# WKUP_CTRL_MMR0_CFG0 register map
Vendor: Texas Instruments
Registers are 32-bit, read-write, reset 0x0 unless marked. A register's access mark holds for its fields unless they carry their own. Offsets are as the file gives them; [hi:lo] are bit positions.

## WKUP_CTRL_MMR0_CFG0 (part 5 of 11)
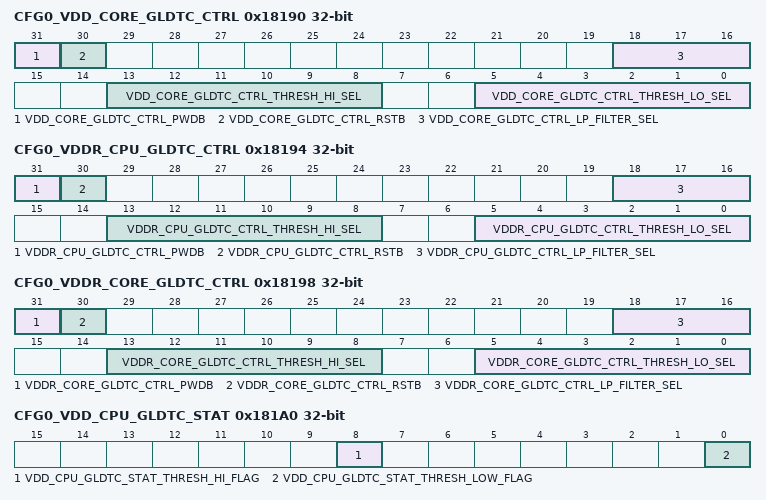
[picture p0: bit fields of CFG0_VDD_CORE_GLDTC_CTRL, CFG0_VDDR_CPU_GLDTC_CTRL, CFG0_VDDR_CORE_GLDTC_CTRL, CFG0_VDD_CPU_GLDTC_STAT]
0x18190 CFG0_VDD_CORE_GLDTC_CTRL — Controls the voltage glitch detector circuit monitoring the VDD_CORE voltage domain
  [31] VDD_CORE_GLDTC_CTRL_PWDB — Power down - active low. 0 - Disable all functions 1 - Enable glitch detectors
  [30] VDD_CORE_GLDTC_CTRL_RSTB — Reset - active low. To ensure proper operation, rstb must be not be de-asserted for at least 100 ns after power-up (pwdb de-asserted). Additionally, rstb must be toggled low at least 200 ns after any change in threshold or low-pass filter settings to prevent abnormal trigger events. 0 - Reset glitch detector flags 1 - Glitch detection flags are enabled
  [18:16] VDD_CORE_GLDTC_CTRL_LP_FILTER_SEL — Selects the glitch detect low-pass filter bandwidth Field values (Others are reserved): 3'b000 - 150 kHz 3'b001 - 125 kHz 3'b010 - 100 kHz 3'b011 - 80 kHz 3'b100 - 60 kHz 3'b101 - 45 kHz 3'b110 - 30 kHz 3'b111 - 15 kHz
  [13:8] VDD_CORE_GLDTC_CTRL_THRESH_HI_SEL — Selects the high voltage glitch threshold as a percentage of the monitored voltage Field values (Others are reserved): 6'b000000 - 93.5% of VDD 6'b000001 - 94.0% of VDD 6'b000010 - 94.5% of VDD 6'b000011 - 95.0% of VDD 6'b000100 - 95.5% of VDD 6'b000101 - 96.0% of VDD 6'b000110 - 96.5% of VDD 6'b000111 - 97.0% of VDD 6'b001000 - 97.5% of VDD 6'b001001 - 98.0% of VDD 6'b001010 - 98.5% of VDD 6'b001011 - 99.0% of VDD 6'b001100 - 99.5% of VDD 6'b001101 - 100.0% of VDD 6'b001110 - 100.5% of VDD 6'b001111 - 101.0% of VDD 6'b010000 - 101.5% of VDD 6'b010001 - 102.0% of VDD 6'b010010 - 102.5% of VDD 6'b010011 - 103.0% of VDD 6'b010100 - 103.5% of VDD 6'b010101 - 104.0% of VDD 6'b010110 - 104.5% of VDD 6'b010111 - 105.0% of VDD 6'b011000 - 105.5% of VDD 6'b011001 - 106.0% of VDD 6'b011010 - 106.5% of VDD 6'b011011 - 107.0% of VDD 6'b011100 - 107.5% of VDD 6'b011101 - 108.0% of VDD 6'b011110 - 108.5% of VDD 6'b011111 - 109.0% of VDD 6'b100000 - 109.5% of VDD 6'b100001 - 110.0% of VDD 6'b100010 - 111.0% of VDD 6'b100011 - 112.0% of VDD 6'b100100 - 113.0% of VDD 6'b100101 - 114.0% of VDD 6'b100110 - 115.0% of VDD 6'b100111 - 116.0% of VDD 6'b101000 - 117.0% of VDD 6'b101001 - 118.0% of VDD 6'b101010 - 119.0% of VDD 6'b101011 - 120.0% of VDD 6'b101100 - 121.0% of VDD 6'b101101 - 122.0% of VDD 6'b101110 - 123.0% of VDD 6'b101111 - 124.0% of VDD 6'b110000 - 125.0% of VDD 6'b110001 - 126.0% of VDD 6'b110010 - 127.0% of VDD 6'b110011 - 128.0% of VDD 6'b110100 - 129.0% of VDD 6'b110101 - 130.0% of VDD 6'b110110 - 131.0% of VDD 6'b110111 - 132.0% of VDD 6'b111000 - 133.0% of VDD 6'b111001 - 134.0% of VDD 6'b111010 - 135.0% of VDD 6'b111011 - 136.0% of VDD 6'b111100 - 137.0% of VDD 6'b111101 - 138.0% of VDD 6'b111110 - 139.0% of VDD 6'b111111 - 140.0% of VDD
  [5:0] VDD_CORE_GLDTC_CTRL_THRESH_LO_SEL — Selects the low voltage glitch threshold as a percentage of the monitored voltage Field values (Others are reserved): 6'b000000 - 106.5% of VDD 6'b000001 - 106.0% of VDD 6'b000010 - 105.5% of VDD 6'b000011 - 105.0% of VDD 6'b000100 - 104.5% of VDD 6'b000101 - 104.0% of VDD 6'b000110 - 103.5% of VDD 6'b000111 - 103.0% of VDD 6'b001000 - 102.5% of VDD 6'b001001 - 102.0% of VDD 6'b001010 - 101.5% of VDD 6'b001011 - 101.0% of VDD 6'b001100 - 100.5% of VDD 6'b001101 - 100.0% of VDD 6'b001110 - 99.5% of VDD 6'b001111 - 99.0% of VDD 6'b010000 - 98.5% of VDD 6'b010001 - 98.0% of VDD 6'b010010 - 97.5% of VDD 6'b010011 - 97.0% of VDD 6'b010100 - 96.5% of VDD 6'b010101 - 96.0% of VDD 6'b010110 - 95.5% of VDD 6'b010111 - 95.0% of VDD 6'b011000 - 94.5% of VDD 6'b011001 - 94.0% of VDD 6'b011010 - 93.5% of VDD 6'b011011 - 93.0% of VDD 6'b011100 - 92.5% of VDD 6'b011101 - 92.0% of VDD 6'b011110 - 91.5% of VDD 6'b011111 - 91.0% of VDD 6'b100000 - 90.5% of VDD 6'b100001 - 90.0% of VDD 6'b100010 - 89.0% of VDD 6'b100011 - 88.0% of VDD 6'b100100 - 87.0% of VDD 6'b100101 - 86.0% of VDD 6'b100110 - 85.0% of VDD 6'b100111 - 84.0% of VDD 6'b101000 - 83.0% of VDD 6'b101001 - 82.0% of VDD 6'b101010 - 81.0% of VDD 6'b101011 - 80.0% of VDD 6'b101100 - 79.0% of VDD 6'b101101 - 78.0% of VDD 6'b101110 - 77.0% of VDD 6'b101111 - 76.0% of VDD 6'b110000 - 75.0% of VDD 6'b110001 - 74.0% of VDD 6'b110010 - 73.0% of VDD 6'b110011 - 72.0% of VDD 6'b110100 - 71.0% of VDD 6'b110101 - 70.0% of VDD 6'b110110 - 69.0% of VDD 6'b110111 - 68.0% of VDD 6'b111000 - 67.0% of VDD 6'b111001 - 66.0% of VDD 6'b111010 - 65.0% of VDD 6'b111011 - 64.0% of VDD 6'b111100 - 63.0% of VDD 6'b111101 - 62.0% of VDD 6'b111110 - 61.0% of VDD 6'b111111 - 60.0% of VDD
0x18194 CFG0_VDDR_CPU_GLDTC_CTRL — Controls the voltage glitch detector circuit monitoring the VDDR_CPU 0 voltage domain
  [31] VDDR_CPU_GLDTC_CTRL_PWDB — Power down - active low. 0 - Disable all functions 1 - Enable glitch detectors
  [30] VDDR_CPU_GLDTC_CTRL_RSTB — Reset - active low. To ensure proper operation, rstb must be not be de-asserted for at least 100 ns after power-up (pwdb de-asserted). Additionally, rstb must be toggled low at least 200 ns after any change in threshold or low-pass filter settings to prevent abnormal trigger events. 0 - Reset glitch detector flags 1 - Glitch detection flags are enabled
  [18:16] VDDR_CPU_GLDTC_CTRL_LP_FILTER_SEL — Selects the glitch detect low-pass filter bandwidth Field values (Others are reserved): 3'b000 - 150 kHz 3'b001 - 125 kHz 3'b010 - 100 kHz 3'b011 - 80 kHz 3'b100 - 60 kHz 3'b101 - 45 kHz 3'b110 - 30 kHz 3'b111 - 15 kHz
  [13:8] VDDR_CPU_GLDTC_CTRL_THRESH_HI_SEL — Selects the high voltage glitch threshold as a percentage of the monitored voltage Field values (Others are reserved): 6'b000000 - 93.5% of VDD 6'b000001 - 94.0% of VDD 6'b000010 - 94.5% of VDD 6'b000011 - 95.0% of VDD 6'b000100 - 95.5% of VDD 6'b000101 - 96.0% of VDD 6'b000110 - 96.5% of VDD 6'b000111 - 97.0% of VDD 6'b001000 - 97.5% of VDD 6'b001001 - 98.0% of VDD 6'b001010 - 98.5% of VDD 6'b001011 - 99.0% of VDD 6'b001100 - 99.5% of VDD 6'b001101 - 100.0% of VDD 6'b001110 - 100.5% of VDD 6'b001111 - 101.0% of VDD 6'b010000 - 101.5% of VDD 6'b010001 - 102.0% of VDD 6'b010010 - 102.5% of VDD 6'b010011 - 103.0% of VDD 6'b010100 - 103.5% of VDD 6'b010101 - 104.0% of VDD 6'b010110 - 104.5% of VDD 6'b010111 - 105.0% of VDD 6'b011000 - 105.5% of VDD 6'b011001 - 106.0% of VDD 6'b011010 - 106.5% of VDD 6'b011011 - 107.0% of VDD 6'b011100 - 107.5% of VDD 6'b011101 - 108.0% of VDD 6'b011110 - 108.5% of VDD 6'b011111 - 109.0% of VDD 6'b100000 - 109.5% of VDD 6'b100001 - 110.0% of VDD 6'b100010 - 111.0% of VDD 6'b100011 - 112.0% of VDD 6'b100100 - 113.0% of VDD 6'b100101 - 114.0% of VDD 6'b100110 - 115.0% of VDD 6'b100111 - 116.0% of VDD 6'b101000 - 117.0% of VDD 6'b101001 - 118.0% of VDD 6'b101010 - 119.0% of VDD 6'b101011 - 120.0% of VDD 6'b101100 - 121.0% of VDD 6'b101101 - 122.0% of VDD 6'b101110 - 123.0% of VDD 6'b101111 - 124.0% of VDD 6'b110000 - 125.0% of VDD 6'b110001 - 126.0% of VDD 6'b110010 - 127.0% of VDD 6'b110011 - 128.0% of VDD 6'b110100 - 129.0% of VDD 6'b110101 - 130.0% of VDD 6'b110110 - 131.0% of VDD 6'b110111 - 132.0% of VDD 6'b111000 - 133.0% of VDD 6'b111001 - 134.0% of VDD 6'b111010 - 135.0% of VDD 6'b111011 - 136.0% of VDD 6'b111100 - 137.0% of VDD 6'b111101 - 138.0% of VDD 6'b111110 - 139.0% of VDD 6'b111111 - 140.0% of VDD
  [5:0] VDDR_CPU_GLDTC_CTRL_THRESH_LO_SEL — Selects the low voltage glitch threshold as a percentage of the monitored voltage Field values (Others are reserved): 6'b000000 - 106.5% of VDD 6'b000001 - 106.0% of VDD 6'b000010 - 105.5% of VDD 6'b000011 - 105.0% of VDD 6'b000100 - 104.5% of VDD 6'b000101 - 104.0% of VDD 6'b000110 - 103.5% of VDD 6'b000111 - 103.0% of VDD 6'b001000 - 102.5% of VDD 6'b001001 - 102.0% of VDD 6'b001010 - 101.5% of VDD 6'b001011 - 101.0% of VDD 6'b001100 - 100.5% of VDD 6'b001101 - 100.0% of VDD 6'b001110 - 99.5% of VDD 6'b001111 - 99.0% of VDD 6'b010000 - 98.5% of VDD 6'b010001 - 98.0% of VDD 6'b010010 - 97.5% of VDD 6'b010011 - 97.0% of VDD 6'b010100 - 96.5% of VDD 6'b010101 - 96.0% of VDD 6'b010110 - 95.5% of VDD 6'b010111 - 95.0% of VDD 6'b011000 - 94.5% of VDD 6'b011001 - 94.0% of VDD 6'b011010 - 93.5% of VDD 6'b011011 - 93.0% of VDD 6'b011100 - 92.5% of VDD 6'b011101 - 92.0% of VDD 6'b011110 - 91.5% of VDD 6'b011111 - 91.0% of VDD 6'b100000 - 90.5% of VDD 6'b100001 - 90.0% of VDD 6'b100010 - 89.0% of VDD 6'b100011 - 88.0% of VDD 6'b100100 - 87.0% of VDD 6'b100101 - 86.0% of VDD 6'b100110 - 85.0% of VDD 6'b100111 - 84.0% of VDD 6'b101000 - 83.0% of VDD 6'b101001 - 82.0% of VDD 6'b101010 - 81.0% of VDD 6'b101011 - 80.0% of VDD 6'b101100 - 79.0% of VDD 6'b101101 - 78.0% of VDD 6'b101110 - 77.0% of VDD 6'b101111 - 76.0% of VDD 6'b110000 - 75.0% of VDD 6'b110001 - 74.0% of VDD 6'b110010 - 73.0% of VDD 6'b110011 - 72.0% of VDD 6'b110100 - 71.0% of VDD 6'b110101 - 70.0% of VDD 6'b110110 - 69.0% of VDD 6'b110111 - 68.0% of VDD 6'b111000 - 67.0% of VDD 6'b111001 - 66.0% of VDD 6'b111010 - 65.0% of VDD 6'b111011 - 64.0% of VDD 6'b111100 - 63.0% of VDD 6'b111101 - 62.0% of VDD 6'b111110 - 61.0% of VDD 6'b111111 - 60.0% of VDD
0x18198 CFG0_VDDR_CORE_GLDTC_CTRL — Controls the voltage glitch detector circuit monitoring the VDDR_CORE voltage domain
  [31] VDDR_CORE_GLDTC_CTRL_PWDB — Power down - active low. 0 - Disable all functions 1 - Enable glitch detectors
  [30] VDDR_CORE_GLDTC_CTRL_RSTB — Reset - active low. To ensure proper operation, rstb must be not be de-asserted for at least 100 ns after power-up (pwdb de-asserted). Additionally, rstb must be toggled low at least 200 ns after any change in threshold or low-pass filter settings to prevent abnormal trigger events. 0 - Reset glitch detector flags 1 - Glitch detection flags are enabled
  [18:16] VDDR_CORE_GLDTC_CTRL_LP_FILTER_SEL — Selects the glitch detect low-pass filter bandwidth Field values (Others are reserved): 3'b000 - 150 kHz 3'b001 - 125 kHz 3'b010 - 100 kHz 3'b011 - 80 kHz 3'b100 - 60 kHz 3'b101 - 45 kHz 3'b110 - 30 kHz 3'b111 - 15 kHz
  [13:8] VDDR_CORE_GLDTC_CTRL_THRESH_HI_SEL — Selects the high voltage glitch threshold as a percentage of the monitored voltage Field values (Others are reserved): 6'b000000 - 93.5% of VDD 6'b000001 - 94.0% of VDD 6'b000010 - 94.5% of VDD 6'b000011 - 95.0% of VDD 6'b000100 - 95.5% of VDD 6'b000101 - 96.0% of VDD 6'b000110 - 96.5% of VDD 6'b000111 - 97.0% of VDD 6'b001000 - 97.5% of VDD 6'b001001 - 98.0% of VDD 6'b001010 - 98.5% of VDD 6'b001011 - 99.0% of VDD 6'b001100 - 99.5% of VDD 6'b001101 - 100.0% of VDD 6'b001110 - 100.5% of VDD 6'b001111 - 101.0% of VDD 6'b010000 - 101.5% of VDD 6'b010001 - 102.0% of VDD 6'b010010 - 102.5% of VDD 6'b010011 - 103.0% of VDD 6'b010100 - 103.5% of VDD 6'b010101 - 104.0% of VDD 6'b010110 - 104.5% of VDD 6'b010111 - 105.0% of VDD 6'b011000 - 105.5% of VDD 6'b011001 - 106.0% of VDD 6'b011010 - 106.5% of VDD 6'b011011 - 107.0% of VDD 6'b011100 - 107.5% of VDD 6'b011101 - 108.0% of VDD 6'b011110 - 108.5% of VDD 6'b011111 - 109.0% of VDD 6'b100000 - 109.5% of VDD 6'b100001 - 110.0% of VDD 6'b100010 - 111.0% of VDD 6'b100011 - 112.0% of VDD 6'b100100 - 113.0% of VDD 6'b100101 - 114.0% of VDD 6'b100110 - 115.0% of VDD 6'b100111 - 116.0% of VDD 6'b101000 - 117.0% of VDD 6'b101001 - 118.0% of VDD 6'b101010 - 119.0% of VDD 6'b101011 - 120.0% of VDD 6'b101100 - 121.0% of VDD 6'b101101 - 122.0% of VDD 6'b101110 - 123.0% of VDD 6'b101111 - 124.0% of VDD 6'b110000 - 125.0% of VDD 6'b110001 - 126.0% of VDD 6'b110010 - 127.0% of VDD 6'b110011 - 128.0% of VDD 6'b110100 - 129.0% of VDD 6'b110101 - 130.0% of VDD 6'b110110 - 131.0% of VDD 6'b110111 - 132.0% of VDD 6'b111000 - 133.0% of VDD 6'b111001 - 134.0% of VDD 6'b111010 - 135.0% of VDD 6'b111011 - 136.0% of VDD 6'b111100 - 137.0% of VDD 6'b111101 - 138.0% of VDD 6'b111110 - 139.0% of VDD 6'b111111 - 140.0% of VDD
  [5:0] VDDR_CORE_GLDTC_CTRL_THRESH_LO_SEL — Selects the low voltage glitch threshold as a percentage of the monitored voltage Field values (Others are reserved): 6'b000000 - 106.5% of VDD 6'b000001 - 106.0% of VDD 6'b000010 - 105.5% of VDD 6'b000011 - 105.0% of VDD 6'b000100 - 104.5% of VDD 6'b000101 - 104.0% of VDD 6'b000110 - 103.5% of VDD 6'b000111 - 103.0% of VDD 6'b001000 - 102.5% of VDD 6'b001001 - 102.0% of VDD 6'b001010 - 101.5% of VDD 6'b001011 - 101.0% of VDD 6'b001100 - 100.5% of VDD 6'b001101 - 100.0% of VDD 6'b001110 - 99.5% of VDD 6'b001111 - 99.0% of VDD 6'b010000 - 98.5% of VDD 6'b010001 - 98.0% of VDD 6'b010010 - 97.5% of VDD 6'b010011 - 97.0% of VDD 6'b010100 - 96.5% of VDD 6'b010101 - 96.0% of VDD 6'b010110 - 95.5% of VDD 6'b010111 - 95.0% of VDD 6'b011000 - 94.5% of VDD 6'b011001 - 94.0% of VDD 6'b011010 - 93.5% of VDD 6'b011011 - 93.0% of VDD 6'b011100 - 92.5% of VDD 6'b011101 - 92.0% of VDD 6'b011110 - 91.5% of VDD 6'b011111 - 91.0% of VDD 6'b100000 - 90.5% of VDD 6'b100001 - 90.0% of VDD 6'b100010 - 89.0% of VDD 6'b100011 - 88.0% of VDD 6'b100100 - 87.0% of VDD 6'b100101 - 86.0% of VDD 6'b100110 - 85.0% of VDD 6'b100111 - 84.0% of VDD 6'b101000 - 83.0% of VDD 6'b101001 - 82.0% of VDD 6'b101010 - 81.0% of VDD 6'b101011 - 80.0% of VDD 6'b101100 - 79.0% of VDD 6'b101101 - 78.0% of VDD 6'b101110 - 77.0% of VDD 6'b101111 - 76.0% of VDD 6'b110000 - 75.0% of VDD 6'b110001 - 74.0% of VDD 6'b110010 - 73.0% of VDD 6'b110011 - 72.0% of VDD 6'b110100 - 71.0% of VDD 6'b110101 - 70.0% of VDD 6'b110110 - 69.0% of VDD 6'b110111 - 68.0% of VDD 6'b111000 - 67.0% of VDD 6'b111001 - 66.0% of VDD 6'b111010 - 65.0% of VDD 6'b111011 - 64.0% of VDD 6'b111100 - 63.0% of VDD 6'b111101 - 62.0% of VDD 6'b111110 - 61.0% of VDD 6'b111111 - 60.0% of VDD
0x181A0 CFG0_VDD_CPU_GLDTC_STAT ro — Shows the status of the voltage glitch detector circuit monitoring the VDD_CPU voltage domain
  [8] VDD_CPU_GLDTC_STAT_THRESH_HI_FLAG — High voltage flag. This flag is cleared by clearing the VDD_CPU_GLDTC_CTRL_rstb bit. 0 - No high voltage detected 1 - Voltage above the high voltage threshold was detected.
  [0] VDD_CPU_GLDTC_STAT_THRESH_LOW_FLAG — Low voltage flag. This flag is cleared by clearing the VDD_CPU_GLDTC_CTRL_rstb bit. 0 - No low voltage detected 1 - Voltage below the low voltage threshold was detected.
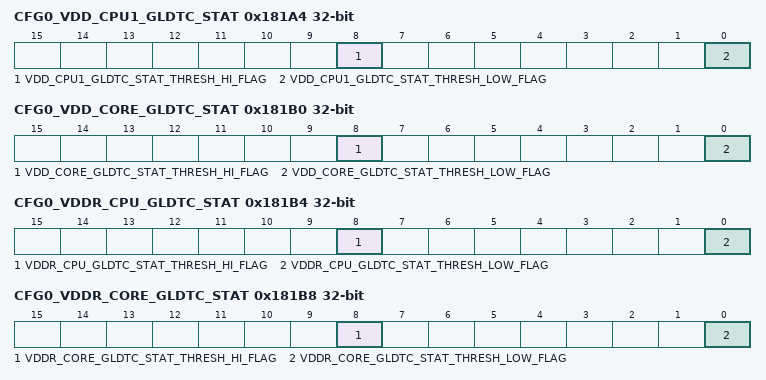
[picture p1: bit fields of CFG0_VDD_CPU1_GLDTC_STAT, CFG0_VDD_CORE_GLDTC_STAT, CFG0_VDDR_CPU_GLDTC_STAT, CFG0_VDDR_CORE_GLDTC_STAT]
0x181A4 CFG0_VDD_CPU1_GLDTC_STAT ro — Shows the status of the voltage glitch detector circuit monitoring the VDD_CPU1 voltage domain (Used for VDD_DDR0)
  [8] VDD_CPU1_GLDTC_STAT_THRESH_HI_FLAG — High voltage flag. This flag is cleared by clearing the VDD_CPU1_GLDTC_CTRL_rstb bit. 0 - No high voltage detected 1 - Voltage above the high voltage threshold was detected.
  [0] VDD_CPU1_GLDTC_STAT_THRESH_LOW_FLAG — Low voltage flag. This flag is cleared by clearing the VDD_CPU1_GLDTC_CTRL_rstb bit. 0 - No low voltage detected 1 - Voltage below the low voltage threshold was detected.
0x181B0 CFG0_VDD_CORE_GLDTC_STAT ro — Shows the status of the voltage glitch detector circuit monitoring the VDD_CORE voltage domain
  [8] VDD_CORE_GLDTC_STAT_THRESH_HI_FLAG — High voltage flag. This flag is cleared by clearing the VDD_CORE_GLDTC_CTRL_rstb bit. 0 - No high voltage detected 1 - Voltage above the high voltage threshold was detected.
  [0] VDD_CORE_GLDTC_STAT_THRESH_LOW_FLAG — Low voltage flag. This flag is cleared by clearing the VDD_CORE_GLDTC_CTRL_rstb bit. 0 - No low voltage detected 1 - Voltage below the low voltage threshold was detected.
0x181B4 CFG0_VDDR_CPU_GLDTC_STAT ro — Shows the status of the voltage glitch detector circuit monitoring the VDDR_CPU voltage domain
  [8] VDDR_CPU_GLDTC_STAT_THRESH_HI_FLAG — High voltage flag. This flag is cleared by clearing the VDDR_CPU_GLDTC_CTRL_rstb bit. 0 - No high voltage detected 1 - Voltage above the high voltage threshold was detected.
  [0] VDDR_CPU_GLDTC_STAT_THRESH_LOW_FLAG — Low voltage flag. This flag is cleared by clearing the VDDR_CPU_GLDTC_CTRL_rstb bit. 0 - No low voltage detected 1 - Voltage below the low voltage threshold was detected.
0x181B8 CFG0_VDDR_CORE_GLDTC_STAT ro — Shows the status of the voltage glitch detector circuit monitoring the VDDR_CORE voltage domain
  [8] VDDR_CORE_GLDTC_STAT_THRESH_HI_FLAG — High voltage flag. This flag is cleared by clearing the VDDR_CORE_GLDTC_CTRL_rstb bit. 0 - No high voltage detected 1 - Voltage above the high voltage threshold was detected.
  [0] VDDR_CORE_GLDTC_STAT_THRESH_LOW_FLAG — Low voltage flag. This flag is cleared by clearing the VDDR_CORE_GLDTC_CTRL_rstb bit. 0 - No low voltage detected 1 - Voltage below the low voltage threshold was detected.
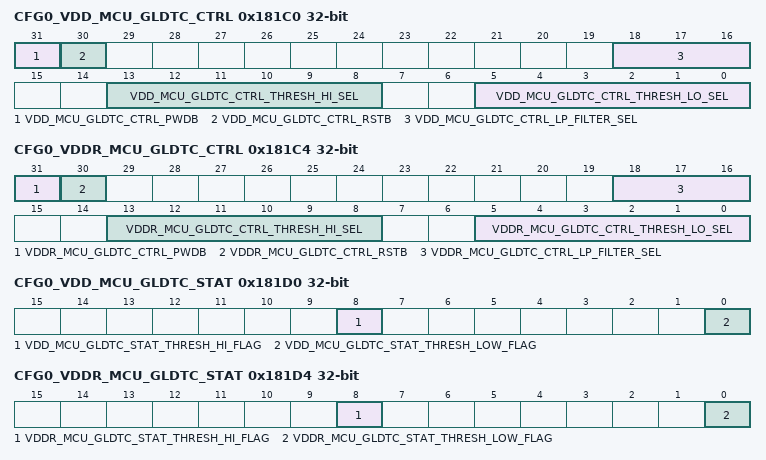
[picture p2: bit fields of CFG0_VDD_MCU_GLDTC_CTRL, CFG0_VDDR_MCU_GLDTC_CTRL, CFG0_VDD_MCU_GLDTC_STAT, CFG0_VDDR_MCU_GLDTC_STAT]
0x181C0 CFG0_VDD_MCU_GLDTC_CTRL — Controls the voltage glitch detector circuit monitoring the VDD_MCU voltage domain
  [31] VDD_MCU_GLDTC_CTRL_PWDB — Power down - active low. 0 - Disable all functions 1 - Enable glitch detectors
  [30] VDD_MCU_GLDTC_CTRL_RSTB — Reset - active low. To ensure proper operation, rstb must be not be de-asserted for at least 100 ns after power-up (pwdb de-asserted). Additionally, rstb must be toggled low at least 200 ns after any change in threshold or low-pass filter settings to prevent abnormal trigger events. 0 - Reset glitch detector flags 1 - Glitch detection flags are enabled
  [18:16] VDD_MCU_GLDTC_CTRL_LP_FILTER_SEL — Selects the glitch detect low-pass filter bandwidth Field values (Others are reserved): 3'b000 - 150 kHz 3'b001 - 125 kHz 3'b010 - 100 kHz 3'b011 - 80 kHz 3'b100 - 60 kHz 3'b101 - 45 kHz 3'b110 - 30 kHz 3'b111 - 15 kHz
  [13:8] VDD_MCU_GLDTC_CTRL_THRESH_HI_SEL — Selects the high voltage glitch threshold as a percentage of the monitored voltage Field values (Others are reserved): 6'b000000 - 93.5% of VDD 6'b000001 - 94.0% of VDD 6'b000010 - 94.5% of VDD 6'b000011 - 95.0% of VDD 6'b000100 - 95.5% of VDD 6'b000101 - 96.0% of VDD 6'b000110 - 96.5% of VDD 6'b000111 - 97.0% of VDD 6'b001000 - 97.5% of VDD 6'b001001 - 98.0% of VDD 6'b001010 - 98.5% of VDD 6'b001011 - 99.0% of VDD 6'b001100 - 99.5% of VDD 6'b001101 - 100.0% of VDD 6'b001110 - 100.5% of VDD 6'b001111 - 101.0% of VDD 6'b010000 - 101.5% of VDD 6'b010001 - 102.0% of VDD 6'b010010 - 102.5% of VDD 6'b010011 - 103.0% of VDD 6'b010100 - 103.5% of VDD 6'b010101 - 104.0% of VDD 6'b010110 - 104.5% of VDD 6'b010111 - 105.0% of VDD 6'b011000 - 105.5% of VDD 6'b011001 - 106.0% of VDD 6'b011010 - 106.5% of VDD 6'b011011 - 107.0% of VDD 6'b011100 - 107.5% of VDD 6'b011101 - 108.0% of VDD 6'b011110 - 108.5% of VDD 6'b011111 - 109.0% of VDD 6'b100000 - 109.5% of VDD 6'b100001 - 110.0% of VDD 6'b100010 - 111.0% of VDD 6'b100011 - 112.0% of VDD 6'b100100 - 113.0% of VDD 6'b100101 - 114.0% of VDD 6'b100110 - 115.0% of VDD 6'b100111 - 116.0% of VDD 6'b101000 - 117.0% of VDD 6'b101001 - 118.0% of VDD 6'b101010 - 119.0% of VDD 6'b101011 - 120.0% of VDD 6'b101100 - 121.0% of VDD 6'b101101 - 122.0% of VDD 6'b101110 - 123.0% of VDD 6'b101111 - 124.0% of VDD 6'b110000 - 125.0% of VDD 6'b110001 - 126.0% of VDD 6'b110010 - 127.0% of VDD 6'b110011 - 128.0% of VDD 6'b110100 - 129.0% of VDD 6'b110101 - 130.0% of VDD 6'b110110 - 131.0% of VDD 6'b110111 - 132.0% of VDD 6'b111000 - 133.0% of VDD 6'b111001 - 134.0% of VDD 6'b111010 - 135.0% of VDD 6'b111011 - 136.0% of VDD 6'b111100 - 137.0% of VDD 6'b111101 - 138.0% of VDD 6'b111110 - 139.0% of VDD 6'b111111 - 140.0% of VDD
  [5:0] VDD_MCU_GLDTC_CTRL_THRESH_LO_SEL — Selects the low voltage glitch threshold as a percentage of the monitored voltage Field values (Others are reserved): 6'b000000 - 106.5% of VDD 6'b000001 - 106.0% of VDD 6'b000010 - 105.5% of VDD 6'b000011 - 105.0% of VDD 6'b000100 - 104.5% of VDD 6'b000101 - 104.0% of VDD 6'b000110 - 103.5% of VDD 6'b000111 - 103.0% of VDD 6'b001000 - 102.5% of VDD 6'b001001 - 102.0% of VDD 6'b001010 - 101.5% of VDD 6'b001011 - 101.0% of VDD 6'b001100 - 100.5% of VDD 6'b001101 - 100.0% of VDD 6'b001110 - 99.5% of VDD 6'b001111 - 99.0% of VDD 6'b010000 - 98.5% of VDD 6'b010001 - 98.0% of VDD 6'b010010 - 97.5% of VDD 6'b010011 - 97.0% of VDD 6'b010100 - 96.5% of VDD 6'b010101 - 96.0% of VDD 6'b010110 - 95.5% of VDD 6'b010111 - 95.0% of VDD 6'b011000 - 94.5% of VDD 6'b011001 - 94.0% of VDD 6'b011010 - 93.5% of VDD 6'b011011 - 93.0% of VDD 6'b011100 - 92.5% of VDD 6'b011101 - 92.0% of VDD 6'b011110 - 91.5% of VDD 6'b011111 - 91.0% of VDD 6'b100000 - 90.5% of VDD 6'b100001 - 90.0% of VDD 6'b100010 - 89.0% of VDD 6'b100011 - 88.0% of VDD 6'b100100 - 87.0% of VDD 6'b100101 - 86.0% of VDD 6'b100110 - 85.0% of VDD 6'b100111 - 84.0% of VDD 6'b101000 - 83.0% of VDD 6'b101001 - 82.0% of VDD 6'b101010 - 81.0% of VDD 6'b101011 - 80.0% of VDD 6'b101100 - 79.0% of VDD 6'b101101 - 78.0% of VDD 6'b101110 - 77.0% of VDD 6'b101111 - 76.0% of VDD 6'b110000 - 75.0% of VDD 6'b110001 - 74.0% of VDD 6'b110010 - 73.0% of VDD 6'b110011 - 72.0% of VDD 6'b110100 - 71.0% of VDD 6'b110101 - 70.0% of VDD 6'b110110 - 69.0% of VDD 6'b110111 - 68.0% of VDD 6'b111000 - 67.0% of VDD 6'b111001 - 66.0% of VDD 6'b111010 - 65.0% of VDD 6'b111011 - 64.0% of VDD 6'b111100 - 63.0% of VDD 6'b111101 - 62.0% of VDD 6'b111110 - 61.0% of VDD 6'b111111 - 60.0% of VDD
0x181C4 CFG0_VDDR_MCU_GLDTC_CTRL — Controls the voltage glitch detector circuit monitoring the VDDR_MCU voltage domain
  [31] VDDR_MCU_GLDTC_CTRL_PWDB — Power down - active low. 0 - Disable all functions 1 - Enable glitch detectors
  [30] VDDR_MCU_GLDTC_CTRL_RSTB — Reset - active low. To ensure proper operation, rstb must be not be de-asserted for at least 100 ns after power-up (pwdb de-asserted). Additionally, rstb must be toggled low at least 200 ns after any change in threshold or low-pass filter settings to prevent abnormal trigger events. 0 - Reset glitch detector flags 1 - Glitch detection flags are enabled
  [18:16] VDDR_MCU_GLDTC_CTRL_LP_FILTER_SEL — Selects the glitch detect low-pass filter bandwidth Field values (Others are reserved): 3'b000 - 150 kHz 3'b001 - 125 kHz 3'b010 - 100 kHz 3'b011 - 80 kHz 3'b100 - 60 kHz 3'b101 - 45 kHz 3'b110 - 30 kHz 3'b111 - 15 kHz
  [13:8] VDDR_MCU_GLDTC_CTRL_THRESH_HI_SEL — Selects the high voltage glitch threshold as a percentage of the monitored voltage Field values (Others are reserved): 6'b000000 - 93.5% of VDD 6'b000001 - 94.0% of VDD 6'b000010 - 94.5% of VDD 6'b000011 - 95.0% of VDD 6'b000100 - 95.5% of VDD 6'b000101 - 96.0% of VDD 6'b000110 - 96.5% of VDD 6'b000111 - 97.0% of VDD 6'b001000 - 97.5% of VDD 6'b001001 - 98.0% of VDD 6'b001010 - 98.5% of VDD 6'b001011 - 99.0% of VDD 6'b001100 - 99.5% of VDD 6'b001101 - 100.0% of VDD 6'b001110 - 100.5% of VDD 6'b001111 - 101.0% of VDD 6'b010000 - 101.5% of VDD 6'b010001 - 102.0% of VDD 6'b010010 - 102.5% of VDD 6'b010011 - 103.0% of VDD 6'b010100 - 103.5% of VDD 6'b010101 - 104.0% of VDD 6'b010110 - 104.5% of VDD 6'b010111 - 105.0% of VDD 6'b011000 - 105.5% of VDD 6'b011001 - 106.0% of VDD 6'b011010 - 106.5% of VDD 6'b011011 - 107.0% of VDD 6'b011100 - 107.5% of VDD 6'b011101 - 108.0% of VDD 6'b011110 - 108.5% of VDD 6'b011111 - 109.0% of VDD 6'b100000 - 109.5% of VDD 6'b100001 - 110.0% of VDD 6'b100010 - 111.0% of VDD 6'b100011 - 112.0% of VDD 6'b100100 - 113.0% of VDD 6'b100101 - 114.0% of VDD 6'b100110 - 115.0% of VDD 6'b100111 - 116.0% of VDD 6'b101000 - 117.0% of VDD 6'b101001 - 118.0% of VDD 6'b101010 - 119.0% of VDD 6'b101011 - 120.0% of VDD 6'b101100 - 121.0% of VDD 6'b101101 - 122.0% of VDD 6'b101110 - 123.0% of VDD 6'b101111 - 124.0% of VDD 6'b110000 - 125.0% of VDD 6'b110001 - 126.0% of VDD 6'b110010 - 127.0% of VDD 6'b110011 - 128.0% of VDD 6'b110100 - 129.0% of VDD 6'b110101 - 130.0% of VDD 6'b110110 - 131.0% of VDD 6'b110111 - 132.0% of VDD 6'b111000 - 133.0% of VDD 6'b111001 - 134.0% of VDD 6'b111010 - 135.0% of VDD 6'b111011 - 136.0% of VDD 6'b111100 - 137.0% of VDD 6'b111101 - 138.0% of VDD 6'b111110 - 139.0% of VDD 6'b111111 - 140.0% of VDD
  [5:0] VDDR_MCU_GLDTC_CTRL_THRESH_LO_SEL — Selects the low voltage glitch threshold as a percentage of the monitored voltage Field values (Others are reserved): 6'b000000 - 106.5% of VDD 6'b000001 - 106.0% of VDD 6'b000010 - 105.5% of VDD 6'b000011 - 105.0% of VDD 6'b000100 - 104.5% of VDD 6'b000101 - 104.0% of VDD 6'b000110 - 103.5% of VDD 6'b000111 - 103.0% of VDD 6'b001000 - 102.5% of VDD 6'b001001 - 102.0% of VDD 6'b001010 - 101.5% of VDD 6'b001011 - 101.0% of VDD 6'b001100 - 100.5% of VDD 6'b001101 - 100.0% of VDD 6'b001110 - 99.5% of VDD 6'b001111 - 99.0% of VDD 6'b010000 - 98.5% of VDD 6'b010001 - 98.0% of VDD 6'b010010 - 97.5% of VDD 6'b010011 - 97.0% of VDD 6'b010100 - 96.5% of VDD 6'b010101 - 96.0% of VDD 6'b010110 - 95.5% of VDD 6'b010111 - 95.0% of VDD 6'b011000 - 94.5% of VDD 6'b011001 - 94.0% of VDD 6'b011010 - 93.5% of VDD 6'b011011 - 93.0% of VDD 6'b011100 - 92.5% of VDD 6'b011101 - 92.0% of VDD 6'b011110 - 91.5% of VDD 6'b011111 - 91.0% of VDD 6'b100000 - 90.5% of VDD 6'b100001 - 90.0% of VDD 6'b100010 - 89.0% of VDD 6'b100011 - 88.0% of VDD 6'b100100 - 87.0% of VDD 6'b100101 - 86.0% of VDD 6'b100110 - 85.0% of VDD 6'b100111 - 84.0% of VDD 6'b101000 - 83.0% of VDD 6'b101001 - 82.0% of VDD 6'b101010 - 81.0% of VDD 6'b101011 - 80.0% of VDD 6'b101100 - 79.0% of VDD 6'b101101 - 78.0% of VDD 6'b101110 - 77.0% of VDD 6'b101111 - 76.0% of VDD 6'b110000 - 75.0% of VDD 6'b110001 - 74.0% of VDD 6'b110010 - 73.0% of VDD 6'b110011 - 72.0% of VDD 6'b110100 - 71.0% of VDD 6'b110101 - 70.0% of VDD 6'b110110 - 69.0% of VDD 6'b110111 - 68.0% of VDD 6'b111000 - 67.0% of VDD 6'b111001 - 66.0% of VDD 6'b111010 - 65.0% of VDD 6'b111011 - 64.0% of VDD 6'b111100 - 63.0% of VDD 6'b111101 - 62.0% of VDD 6'b111110 - 61.0% of VDD 6'b111111 - 60.0% of VDD
0x181D0 CFG0_VDD_MCU_GLDTC_STAT ro — Shows the status of the voltage glitch detector circuit monitoring the VDD_MCU voltage domain
  [8] VDD_MCU_GLDTC_STAT_THRESH_HI_FLAG — High voltage flag. This flag is cleared by clearing the VDD_MCU_GLDTC_CTRL_rstb bit. 0 - No high voltage detected 1 - Voltage above the high voltage threshold was detected.
  [0] VDD_MCU_GLDTC_STAT_THRESH_LOW_FLAG — Low voltage flag. This flag is cleared by clearing the VDD_MCU_GLDTC_CTRL_rstb bit. 0 - No low voltage detected 1 - Voltage below the low voltage threshold was detected.
0x181D4 CFG0_VDDR_MCU_GLDTC_STAT ro — Shows the status of the voltage glitch detector circuit monitoring the VDDR_MCU voltage domain
  [8] VDDR_MCU_GLDTC_STAT_THRESH_HI_FLAG — High voltage flag. This flag is cleared by clearing the VDDR_MCU_GLDTC_CTRL_rstb bit. 0 - No high voltage detected 1 - Voltage above the high voltage threshold was detected.
  [0] VDDR_MCU_GLDTC_STAT_THRESH_LOW_FLAG — Low voltage flag. This flag is cleared by clearing the VDDR_MCU_GLDTC_CTRL_rstb bit. 0 - No low voltage detected 1 - Voltage below the low voltage threshold was detected.
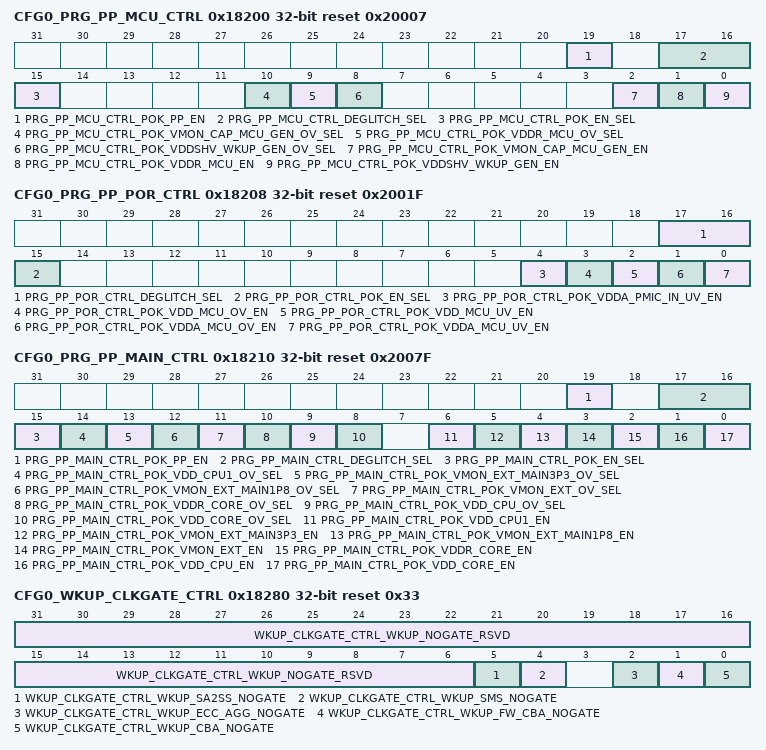
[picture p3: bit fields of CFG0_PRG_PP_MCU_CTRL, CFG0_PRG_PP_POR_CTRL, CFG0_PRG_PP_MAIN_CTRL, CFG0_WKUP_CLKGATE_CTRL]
0x18200 CFG0_PRG_PP_MCU_CTRL reset 0x20007 — Configures the MCU PRG_PP controller
  [19] PRG_PP_MCU_CTRL_POK_PP_EN — POK ping-pong enable. When set, enables automatic switching between undervoltage and overvoltage detection on VDDSHV_WKUP_GENERAL, VDDR_MCU and VMON_CAP_MCU_GENERAL POKs. This bit has no effect if the POK's ov_sel bit = 1. 0 - No pingpong operation. UV/OV operation selected by each POK ov_sel bit 1 - Pingpong operation enabled .
  [17:16] PRG_PP_MCU_CTRL_DEGLITCH_SEL — Deglitch period for PRG_PP_MCU POKs Field values (Others are reserved): 2'b00 - 5 us 2'b01 - 10 us 2'b10 - 15 us 2'b11 - 20 us
  [15] PRG_PP_MCU_CTRL_POK_EN_SEL — Select POK enable source 0 - POK enables come from hardware tie-offs (tie-offs are 0 on this device so all POKs are disabled on power-up) 1 - POK enables come from PRG_PP_MCU_CTRL register
  [10] PRG_PP_MCU_CTRL_POK_VMON_CAP_MCU_GEN_OV_SEL — Force VMON_CAP_MCU_GENERAL POK overvoltage detection. If this bit is 0 and pok_pp_en bit is also 0 then only undervoltage detection is enabled. 0 - Undervoltage detection or UV/OV ping-pong operation 1- Overvoltage detection only
  [9] PRG_PP_MCU_CTRL_POK_VDDR_MCU_OV_SEL — Force VDDR_MCU POK overvoltage detection. If this bit is 0 and pok_pp_en bit is also 0 then only undervoltage detection is enabled. 0 - Undervoltage detection or UV/OV ping-pong operation 1- Overvoltage detection only
  [8] PRG_PP_MCU_CTRL_POK_VDDSHV_WKUP_GEN_OV_SEL — Force VDDSHV_WKUP_GENERAL POK overvoltage detection. If this bit is 0 and pok_pp_en bit is also 0 then only undervoltage detection is enabled. 0 - Undervoltage detection or UV/OV ping-pong operation 1- Overvoltage detection only
  [2] PRG_PP_MCU_CTRL_POK_VMON_CAP_MCU_GEN_EN — Enable VMON_CAP_MCU_GENERAL POK detection 0 - POK detection disabled 1 - POK detection enabled
  [1] PRG_PP_MCU_CTRL_POK_VDDR_MCU_EN — Enable VDDR_MCU POK detection 0 - POK detection disabled 1 - POK detection enabled
  [0] PRG_PP_MCU_CTRL_POK_VDDSHV_WKUP_GEN_EN — Enable VDDSHV_WKUP_GENERAL POK detection 0 - POK detection disabled 1 - POK detection enabled
0x18208 CFG0_PRG_PP_POR_CTRL reset 0x2001F — Configures the POR PRG_PP controller
  [17:16] PRG_PP_POR_CTRL_DEGLITCH_SEL — Deglitch period for PRG_PP_POR POKs Field values (Others are reserved): 2'b00 - 5 us 2'b01 - 10 us 2'b10 - 15 us 2'b11 - 20 us
  [15] PRG_PP_POR_CTRL_POK_EN_SEL — Select POK enable source 0 - POK enables come from hardware tie-offs (tie-offs are 0 on this device so all POKs are disabled on power-up) 1 - POK enables come from PRG_PP_POR_CTRL register
  [4] PRG_PP_POR_CTRL_POK_VDDA_PMIC_IN_UV_EN — Enable VDDA_PMIC_IN undervoltage POK detection 0 - POK detection disabled 1 - POK detection enabled
  [3] PRG_PP_POR_CTRL_POK_VDD_MCU_OV_EN — Enable VDD_MCU overvoltage POK detection 0 - POK detection disabled 1 - POK detection enabled
  [2] PRG_PP_POR_CTRL_POK_VDD_MCU_UV_EN — Enable VDD_MCU undervoltage POK detection 0 - POK detection disabled 1 - POK detection enabled
  [1] PRG_PP_POR_CTRL_POK_VDDA_MCU_OV_EN — Enable 1.8V VDDA_MCU overvoltage POK detection 0 - POK detection disabled 1 - POK detection enabled
  [0] PRG_PP_POR_CTRL_POK_VDDA_MCU_UV_EN — Enable 1.8V VDDA_MCU undervoltage POK detection 0 - POK detection disabled 1 - POK detection enabled
0x18210 CFG0_PRG_PP_MAIN_CTRL reset 0x2007F — Configures the MAIN PRG_PP controller
  [19] PRG_PP_MAIN_CTRL_POK_PP_EN — POK ping-pong enable. When set, enables automatic switching between undervoltage and overvoltage detection on VDD_CORE, VDD_CPU, VDDR_CORE, VMON_EXT, VMON_EXT_MAIN1P8 and VMON_EXT_MAIN3P3. This bit has no effect if the POK's ov_sel bit = 1. 0 - No pingpong operation. UV/OV operation selected by each POK ov_sel bit 1 - Pingpong operation enabled .
  [17:16] PRG_PP_MAIN_CTRL_DEGLITCH_SEL — Deglitch period for PRG_PP_MAIN POKs Field values (Others are reserved): 2'b00 - 5 us 2'b01 - 10 us 2'b10 - 15 us 2'b11 - 20 us
  [15] PRG_PP_MAIN_CTRL_POK_EN_SEL — Select POK enable source 0 - POK enables come from hardware tie-offs (tie-offs are 0 on this device so all POKs are disabled on power-up) 1 - POK enables come from PRG_PP_MAIN_CTRL register
  [14] PRG_PP_MAIN_CTRL_POK_VDD_CPU1_OV_SEL — Force VDD_CPU1 POK overvoltage detection. If this bit is 0 and pok_pp_en bit is also 0 then only undervoltage detection is enabled. 0 - Undervoltage detection or UV/OV ping-pong operation 1- Overvoltage detection only
  [13] PRG_PP_MAIN_CTRL_POK_VMON_EXT_MAIN3P3_OV_SEL — Force VMON_EXT_MAIN 3.3V POK overvoltage detection. If this bit is 0 and pok_pp_en bit is also 0 then only undervoltage detection is enabled. 0 - Undervoltage detection or UV/OV ping-pong operation 1- Overvoltage detection only
  [12] PRG_PP_MAIN_CTRL_POK_VMON_EXT_MAIN1P8_OV_SEL — Force VMON_EXT_MAIN 1.8V POK overvoltage detection. If this bit is 0 and pok_pp_en bit is also 0 then only undervoltage detection is enabled. 0 - Undervoltage detection or UV/OV ping-pong operation 1- Overvoltage detection only
  [11] PRG_PP_MAIN_CTRL_POK_VMON_EXT_OV_SEL — Force VMON_EXT POK overvoltage detection. If this bit is 0 and pok_pp_en bit is also 0 then only undervoltage detection is enabled. 0 - Undervoltage detection or UV/OV ping-pong operation 1- Overvoltage detection only
  [10] PRG_PP_MAIN_CTRL_POK_VDDR_CORE_OV_SEL — Force VDDR_CORE POK overvoltage detection. If this bit is 0 and pok_pp_en bit is also 0 then only undervoltage detection is enabled. 0 - Undervoltage detection or UV/OV ping-pong operation 1- Overvoltage detection only
  [9] PRG_PP_MAIN_CTRL_POK_VDD_CPU_OV_SEL — Force VDD_CPU POK overvoltage detection. If this bit is 0 and pok_pp_en bit is also 0 then only undervoltage detection is enabled. 0 - Undervoltage detection or UV/OV ping-pong operation 1- Overvoltage detection only
  [8] PRG_PP_MAIN_CTRL_POK_VDD_CORE_OV_SEL — Force VDD_CORE POK overvoltage detection. If this bit is 0 and pok_pp_en bit is also 0 then only undervoltage detection is enabled. 0 - Undervoltage detection or UV/OV ping-pong operation 1- Overvoltage detection only
  [6] PRG_PP_MAIN_CTRL_POK_VDD_CPU1_EN — Enable VDD_CPU1 POK detection 0 - POK detection disabled 1 - POK detection enabled
  [5] PRG_PP_MAIN_CTRL_POK_VMON_EXT_MAIN3P3_EN — Enable VMON_EXT_MAIN 3.3V POK detection 0 - POK detection disabled 1 - POK detection enabled
  [4] PRG_PP_MAIN_CTRL_POK_VMON_EXT_MAIN1P8_EN — Enable VMON_EXT_MAIN 1.8V POK detection 0 - POK detection disabled 1 - POK detection enabled
  [3] PRG_PP_MAIN_CTRL_POK_VMON_EXT_EN — Enable VMON_EXT POK detection 0 - POK detection disabled 1 - POK detection enabled
  [2] PRG_PP_MAIN_CTRL_POK_VDDR_CORE_EN — Enable VDDR_CORE POK detection 0 - POK detection disabled 1 - POK detection enabled
  [1] PRG_PP_MAIN_CTRL_POK_VDD_CPU_EN — Enable VDD_CPU POK detection 0 - POK detection disabled 1 - POK detection enabled
  [0] PRG_PP_MAIN_CTRL_POK_VDD_CORE_EN — Enable VDD_CORE POK detection 0 - POK detection disabled 1 - POK detection enabled
0x18280 CFG0_WKUP_CLKGATE_CTRL reset 0x33 — Controls the power clock gating feature of WKUP domain modules and busses
  [31:6] WKUP_CLKGATE_CTRL_WKUP_NOGATE_RSVD — WKUP reserved clock gate disable. These bits should remain unchanged (written only with their default value) to maintain compatibility with future devices. 0 - Clocks are gated on idle for power savings 1 - Clocks are not gated on idle, power saving disabled
  [5] WKUP_CLKGATE_CTRL_WKUP_SA2SS_NOGATE — WKUP SA2SS clock gate disable 0 - Clocks are gated on idle for power savings 1 - Clocks are not gated on idle, power saving disabled
  [4] WKUP_CLKGATE_CTRL_WKUP_SMS_NOGATE — WKUP SMS clock gate disable 0 - Clocks are gated on idle for power savings 1 - Clocks are not gated on idle, power saving disabled
  [2] WKUP_CLKGATE_CTRL_WKUP_ECC_AGG_NOGATE — WKUP ECC Aggregator clock gate disable 0 - Clocks are gated on idle for power savings 1 - Clocks are not gated on idle, power saving disabled
  [1] WKUP_CLKGATE_CTRL_WKUP_FW_CBA_NOGATE — WKUP domain Firewall bus (wkup_fw_cbass) clock gate disable 0 - Clocks are gated on idle for power savings 1 - Clocks are not gated on idle, power saving disabled
  [0] WKUP_CLKGATE_CTRL_WKUP_CBA_NOGATE — WKUP domain Data bus (wkup_cbass) clock gate disable 0 - Clocks are gated on idle for power savings 1 - Clocks are not gated on idle, power saving disabled
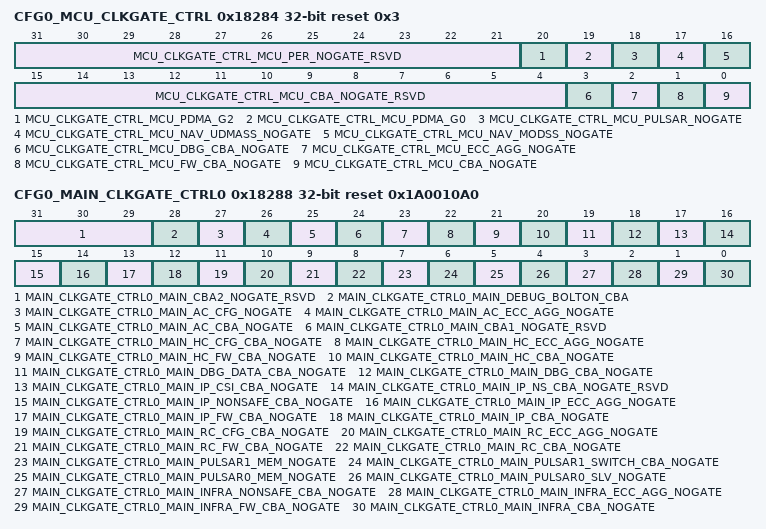
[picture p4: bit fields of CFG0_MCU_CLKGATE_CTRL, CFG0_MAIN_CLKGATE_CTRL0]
0x18284 CFG0_MCU_CLKGATE_CTRL reset 0x3 — Controls the power clock gating feature of MCU domain modules and busses
  [31:21] MCU_CLKGATE_CTRL_MCU_PER_NOGATE_RSVD — MCU reserved clock gate disable. These bits should remain unchanged (written only with their default value) to maintain compatibility with future devices. 0 - Clocks are gated on idle for power savings 1 - Clocks are not gated on idle, power saving disabled
  [20] MCU_CLKGATE_CTRL_MCU_PDMA_G2 — MCU domain MCAN1/USART0 PDMA clock gate disable. 0 - Clocks are gated on idle for power savings 1 - Clocks are not gated on idle, power saving disabled
  [19] MCU_CLKGATE_CTRL_MCU_PDMA_G0 — MCU domain MCAN0/SPI0 PDMA clock gate disable. 0 - Clocks are gated on idle for power savings 1 - Clocks are not gated on idle, power saving disabled
  [18] MCU_CLKGATE_CTRL_MCU_PULSAR_NOGATE — MCU domain Pulsar clock gate disable. 0 - Clocks are gated on idle for power savings 1 - Clocks are not gated on idle, power saving disabled
  [17] MCU_CLKGATE_CTRL_MCU_NAV_UDMASS_NOGATE — MCU NavSS UDMA interface clock gate disable. 0 - Clocks are gated on idle for power savings 1 - Clocks are not gated on idle, power saving disabled
  [16] MCU_CLKGATE_CTRL_MCU_NAV_MODSS_NOGATE — MCU NavSS MODSS interface clock gate disable. 0 - Clocks are gated on idle for power savings 1 - Clocks are not gated on idle, power saving disabled
  [15:4] MCU_CLKGATE_CTRL_MCU_CBA_NOGATE_RSVD — MCU reserved clock gate disable. These bits should remain unchanged (written only with their default value) to maintain compatibility with future devices. 0 - Clocks are gated on idle for power savings 1 - Clocks are not gated on idle, power saving disabled
  [3] MCU_CLKGATE_CTRL_MCU_DBG_CBA_NOGATE — MCU domain Debug bus (mcu_dbg_cbass) clock gate disable. 0 - Clocks are gated on idle for power savings 1 - Clocks are not gated on idle, power saving disabled
  [2] MCU_CLKGATE_CTRL_MCU_ECC_AGG_NOGATE — MCU ECC Aggregator clock gate disable 0 - Clocks are gated on idle for power savings 1 - Clocks are not gated on idle, power saving disabled
  [1] MCU_CLKGATE_CTRL_MCU_FW_CBA_NOGATE — MCU domain Firewall bus (mcu_fw_cbass) clock gate disable. 0 - Clocks are gated on idle for power savings 1 - Clocks are not gated on idle, power saving disabled
  [0] MCU_CLKGATE_CTRL_MCU_CBA_NOGATE — MCU domain Data bus (mcu_cbass) clock gate disable. 0 - Clocks are gated on idle for power savings 1 - Clocks are not gated on idle, power saving disabled
0x18288 CFG0_MAIN_CLKGATE_CTRL0 reset 0x1A0010A0 — Controls the power clock gating feature of MAIN domain modules and busses
  [31:29] MAIN_CLKGATE_CTRL0_MAIN_CBA2_NOGATE_RSVD — MAIN CBA reserved clock gate disable. These bits should remain unchanged (written only with their default value) to maintain compatibility with future devices. 0 - Clocks are gated on idle for power savings 1 - Clocks are not gated on idle, power saving disabled
  [28] MAIN_CLKGATE_CTRL0_MAIN_DEBUG_BOLTON_CBA — MAIN domain debug bolton bus (debug_bolton_cbass) clock gate disable. 0 - Clocks are gated on idle for power savings 1 - Clocks are not gated on idle, power saving disabled
  [27] MAIN_CLKGATE_CTRL0_MAIN_AC_CFG_NOGATE — MAIN domain AC Configuration bus (ac_cfg_fw_cbass) clock gate disable. 0 - Clocks are gated on idle for power savings 1 - Clocks are not gated on idle, power saving disabled
  [26] MAIN_CLKGATE_CTRL0_MAIN_AC_ECC_AGG_NOGATE — MAIN domain AC ECC aggregator bus (ac_pipe_ecc_aggr) clock gate disable. 0 - Clocks are gated on idle for power savings 1 - Clocks are not gated on idle, power saving disabled
  [25] MAIN_CLKGATE_CTRL0_MAIN_AC_CBA_NOGATE — MAIN domain AC Firewall bus (ac_pipe_cbass_main_fw_cbass_0) clock gate disable. 0 - Clocks are gated on idle for power savings 1 - Clocks are not gated on idle, power saving disabled
  [24] MAIN_CLKGATE_CTRL0_MAIN_CBA1_NOGATE_RSVD — MAIN CBA reserved clock gate disable. These bits should remain unchanged (written only with their default value) to maintain compatibility with future devices. 0 - Clocks are gated on idle for power savings 1 - Clocks are not gated on idle, power saving disabled
  [23] MAIN_CLKGATE_CTRL0_MAIN_HC_CFG_CBA_NOGATE — MAIN domain HC Configuration bus (hc_cfg_cbass_0) clock gate disable. 0 - Clocks are gated on idle for power savings 1 - Clocks are not gated on idle, power saving disabled
  [22] MAIN_CLKGATE_CTRL0_MAIN_HC_ECC_AGG_NOGATE — MAIN domain HC ECC aggregator (nogate) clock gate disable. 0 - Clocks are gated on idle for power savings 1 - Clocks are not gated on idle, power saving disabled
  [21] MAIN_CLKGATE_CTRL0_MAIN_HC_FW_CBA_NOGATE — MAIN domain HC Firewall bus (main_hc2_fw_cbass_0) clock gate disable. 0 - Clocks are gated on idle for power savings 1 - Clocks are not gated on idle, power saving disabled
  [20] MAIN_CLKGATE_CTRL0_MAIN_HC_CBA_NOGATE — MAIN domain HC Data bus (hc2_cbass_0) clock gate disable. 0 - Clocks are gated on idle for power savings 1 - Clocks are not gated on idle, power saving disabled
  [19] MAIN_CLKGATE_CTRL0_MAIN_DBG_DATA_CBA_NOGATE — MAIN domain Debug Data bus (debug_cbass) clock gate disable. 0 - Clocks are gated on idle for power savings 1 - Clocks are not gated on idle, power saving disabled
  [18] MAIN_CLKGATE_CTRL0_MAIN_DBG_CBA_NOGATE — MAIN domain Debug bus (debug_cbass_wrap_main_0) clock gate disable. 0 - Clocks are gated on idle for power savings 1 - Clocks are not gated on idle, power saving disabled
  [17] MAIN_CLKGATE_CTRL0_MAIN_IP_CSI_CBA_NOGATE — MAIN domain CSI bus (csi_cbass_0) clock gate disable. 0 - Clocks are gated on idle for power savings 1 - Clocks are not gated on idle, power saving disabled
  [16] MAIN_CLKGATE_CTRL0_MAIN_IP_NS_CBA_NOGATE_RSVD — MAIN nonsafety CBA reserved clock gate disable. These bits should remain unchanged (written only with their default value) to maintain compatibility with future devices. 0 - Clocks are gated on idle for power savings 1 - Clocks are not gated on idle, power saving disabled
  [15] MAIN_CLKGATE_CTRL0_MAIN_IP_NONSAFE_CBA_NOGATE — MAIN domain Interface Peripheral nonsafety IP bus (ipphy_cbass_0) clock gate disable. 0 - Clocks are gated on idle for power savings 1 - Clocks are not gated on idle, power saving disabled
  [14] MAIN_CLKGATE_CTRL0_MAIN_IP_ECC_AGG_NOGATE — MAIN domain Interface Peripheral ECC aggregator (main_spi0_g0_main_0_ecc_aggr_main_0) clock gate disable. 0 - Clocks are gated on idle for power savings 1 - Clocks are not gated on idle, power saving disabled
  [13] MAIN_CLKGATE_CTRL0_MAIN_IP_FW_CBA_NOGATE — MAIN domain Interface Peripheral Firewall bus (ipphy_cbass_main_fw_cbass) clock gate disable. 0 - Clocks are gated on idle for power savings 1 - Clocks are not gated on idle, power saving disabled
  [12] MAIN_CLKGATE_CTRL0_MAIN_IP_CBA_NOGATE — MAIN domain Interface Peripheral bus (ipphy_safe_cbass_0) clock gate disable. 0 - Clocks are gated on idle for power savings 1 - Clocks are not gated on idle, power saving disabled
  [11] MAIN_CLKGATE_CTRL0_MAIN_RC_CFG_CBA_NOGATE — MAIN domain RC Configuration bus (rc_cfg_cbass_0) clock gate disable. 0 - Clocks are gated on idle for power savings 1 - Clocks are not gated on idle, power saving disabled
  [10] MAIN_CLKGATE_CTRL0_MAIN_RC_ECC_AGG_NOGATE — MAIN domain RC ECC aggregator (main_rc_ecc_aggr_main_0) clock gate disable. 0 - Clocks are gated on idle for power savings 1 - Clocks are not gated on idle, power saving disabled
  [9] MAIN_CLKGATE_CTRL0_MAIN_RC_FW_CBA_NOGATE — MAIN domain RC Firewall bus (rc_cbass_main_fw_cbass) clock gate disable. 0 - Clocks are gated on idle for power savings 1 - Clocks are not gated on idle, power saving disabled
  [8] MAIN_CLKGATE_CTRL0_MAIN_RC_CBA_NOGATE — MAIN domain RC Data bus (rc_cbass_0) clock gate disable. 0 - Clocks are gated on idle for power savings 1 - Clocks are not gated on idle, power saving disabled
  [7] MAIN_CLKGATE_CTRL0_MAIN_PULSAR1_MEM_NOGATE — MAIN domain Pulsar 1 memory bus (pulsar1_mem_cbass) clock gate disable. 0 - Clocks are gated on idle for power savings 1 - Clocks are not gated on idle, power saving disabled
  [6] MAIN_CLKGATE_CTRL0_MAIN_PULSAR1_SWITCH_CBA_NOGATE — MAIN domain Pulsar 1 peripheral switch bus (pulsar1_periph_switch_cbass) clock gate disable. 0 - Clocks are gated on idle for power savings 1 - Clocks are not gated on idle, power saving disabled
  [5] MAIN_CLKGATE_CTRL0_MAIN_PULSAR0_MEM_NOGATE — MAIN domain Pulsar 0 memory bus (pulsar0_mem_cbass) clock gate disable. 0 - Clocks are gated on idle for power savings 1 - Clocks are not gated on idle, power saving disabled
  [4] MAIN_CLKGATE_CTRL0_MAIN_PULSAR0_SLV_NOGATE — MAIN domain Pulsar slave bus (pulsar0_slv_cbass) clock gate disable. 0 - Clocks are gated on idle for power savings 1 - Clocks are not gated on idle, power saving disabled
  [3] MAIN_CLKGATE_CTRL0_MAIN_INFRA_NONSAFE_CBA_NOGATE — MAIN domain Infrastructure non-safety IP bus (main_infra_non_safe_cbass) clock gate disable. 0 - Clocks are gated on idle for power savings 1 - Clocks are not gated on idle, power saving disabled
  [2] MAIN_CLKGATE_CTRL0_MAIN_INFRA_ECC_AGG_NOGATE — MAIN domain Infrastructure ECC aggregator (main_infra_ecc_aggr) clock gate disable. 0 - Clocks are gated on idle for power savings 1 - Clocks are not gated on idle, power saving disabled
  [1] MAIN_CLKGATE_CTRL0_MAIN_INFRA_FW_CBA_NOGATE — MAIN domain Infrastructure Firewall bus (main_infra_fw_cbass) clock gate disable. 0 - Clocks are gated on idle for power savings 1 - Clocks are not gated on idle, power saving disabled
  [0] MAIN_CLKGATE_CTRL0_MAIN_INFRA_CBA_NOGATE — MAIN domain Infrastructure bus (main_infra_cbass) clock gate disable. 0 - Clocks are gated on idle for power savings 1 - Clocks are not gated on idle, power saving disabled
